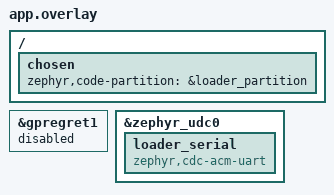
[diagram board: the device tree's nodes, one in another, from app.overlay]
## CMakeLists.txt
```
# SPDX-License-Identifier: MIT
#
# The Neuron's UF2 loader, linked at 0x1000 in front of ZMK. Build it for
# defy_neuron/nrf52833; this module is its board root.

cmake_minimum_required(VERSION 3.20.0)

get_filename_component(module ${CMAKE_CURRENT_LIST_DIR}/../.. ABSOLUTE)
list(APPEND BOARD_ROOT ${module})
list(APPEND DTS_ROOT ${module})

find_package(Zephyr REQUIRED HINTS $ENV{ZEPHYR_BASE})
project(defy_loader)

# src/start.c replaces the soc_reset_hook binding in Nordic's platform_init.ld,
# and Zephyr's Cortex-M reset.S calls the hook before SystemInit(). Another
# version of either file stops the build until start.c is reviewed against it.
include(${module}/cmake/defy_upstream.cmake)
defy_upstream_pin(${ZEPHYR_BASE}/soc/nordic/common/platform_init.ld
                  2e75270bf5d0bfbcefe237fb653c8c4a975bf787b9f60406268f4a7f0cc7279c
                  "the loader's src/start.c")
defy_upstream_pin(${ZEPHYR_BASE}/arch/arm/core/cortex_m/reset.S
                  3245028db3c46e9ed273d4e981f1776d7d1741a02d1fbda7d18617a81e82e74c
                  "the loader's src/start.c")

target_include_directories(app PRIVATE src ${module}/include)
target_sources(app PRIVATE src/start.c src/boot_mode.c src/main.c src/disk.c src/uf2.c
                           src/fat.c src/led.c)
```

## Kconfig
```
# SPDX-License-Identifier: MIT

mainmenu "Defy Neuron UF2 loader"

menu "Defy UF2 loader"

# Placeholder IDs, Zephyr's for testing. They differ from ZMK's 1d50:615e
# because Windows binds drivers by these IDs.
config DEFY_LOADER_USB_VID
    hex "USB vendor ID of the drive"
    default 0x2fe3

config DEFY_LOADER_USB_PID
    hex "USB product ID of the drive"
    default 0x0100

config DEFY_LOADER_USB_MANUFACTURER
    string "USB manufacturer string of the drive"
    default "zmk-defy-wireless"

config DEFY_LOADER_USB_PRODUCT
    string "USB product string of the drive"
    default "Defy UF2 loader"

endmenu

source "Kconfig.zephyr"
```

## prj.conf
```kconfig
# SPDX-License-Identifier: MIT

# The drive: Zephyr's USB device stack with its mass storage and CDC ACM
# classes, one instance each. The serial number comes from hwinfo, as ZMK's
# does; Kconfig in this directory holds the IDs and strings.
CONFIG_USB_DEVICE_STACK_NEXT=y
CONFIG_USBD_MSC_CLASS=y
CONFIG_USBD_CDC_ACM_CLASS=y
CONFIG_HWINFO=y
CONFIG_SERIAL=y
CONFIG_UART_LINE_CTRL=y

# ZMK's code_partition and Dygma's boot request page.
CONFIG_FLASH=y
CONFIG_FLASH_MAP=y
CONFIG_FLASH_PAGE_LAYOUT=y
CONFIG_CRC=y

CONFIG_REBOOT=y
CONFIG_POWEROFF=y

# Nothing reads a log or a console without SWD.
CONFIG_LOG=n
CONFIG_PRINTK=n
CONFIG_CONSOLE=n
CONFIG_BOOT_BANNER=n

# The loader drives no pins but the status LED's, through nrfx's PWM
# registers (src/led.c).
CONFIG_GPIO=n

# Size: the loader has 48 KiB.
CONFIG_LTO=y
CONFIG_ISR_TABLES_LOCAL_DECLARATION=y
CONFIG_COMMON_LIBC_MALLOC=n
CONFIG_TIMESLICING=n
CONFIG_ERRNO=n
CONFIG_FAULT_DUMP=0
```

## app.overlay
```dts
/*
 * The loader runs from loader_partition at 0x1000, where n2_bootloader starts
 * it; code_partition is ZMK's. loader_serial takes the installer's 1200-baud
 * request for n2_bootloader.
 *
 * SPDX-License-Identifier: MIT
 */

/ {
    chosen {
        zephyr,code-partition = &loader_partition;
    };
};

/* No driver for GPREGRET: start.c and main.c own it. */
&gpregret1 {
    status = "disabled";
};

&zephyr_udc0 {
    loader_serial: loader_serial {
        compatible = "zephyr,cdc-acm-uart";
    };
};
```

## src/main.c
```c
/*
 * The loader's drive mode, reached when start.c did not start ZMK. The
 * Neuron shows a USB drive that takes a UF2 file of ZMK (disk.c), and a
 * serial port, and its status LED (led.c) shows what a reset would start.
 * Setting the port to 1200 baud with DTR low, and keeping it so for 250 ms,
 * writes Dygma's boot request and resets into n2_bootloader, as ZMK's Studio
 * port does (docs/software-bootloader.md).
 *
 * ZMK can start when its vector table is valid and start.c did not stop it
 * for failing to confirm its starts. The loader leaves drive mode by a reset
 * into ZMK once a UF2 file has been written; when VBUS goes away while ZMK
 * can start; after a fatal error; and, for a drive shown on request, after
 * IDLE_TIMEOUT_MIN minutes without a UF2 block. Otherwise a VBUS loss powers
 * the Neuron down to System OFF, from which a USB connection wakes it into
 * the drive again. A failed setup, the disk's check included, leaves the
 * same way, except that while VBUS stays and ZMK cannot start, the loader
 * waits for VBUS to go: a reset would only fail again.
 *
 * SPDX-License-Identifier: MIT
 */

#include <errno.h>

#include <zephyr/device.h>
#include <zephyr/drivers/uart.h>
#include <zephyr/fatal.h>
#include <zephyr/kernel.h>
#include <zephyr/storage/flash_map.h>
#include <zephyr/sys/poweroff.h>
#include <zephyr/sys/reboot.h>
#include <zephyr/usb/usbd.h>
#include <hal/nrf_power.h>

#include <dygma/defy_boot_request.h>
#include <dygma/defy_loader.h>

#include "boot_mode.h"
#include "layout.h"
#include "loader.h"

/* The loader runs from loader_partition (app.overlay), and layout.h agrees with the
 * devicetree, which ZMK's board shares. */
BUILD_ASSERT(DT_SAME_NODE(DT_CHOSEN(zephyr_code_partition), DT_NODELABEL(loader_partition)));
BUILD_ASSERT(CONFIG_FLASH_LOAD_OFFSET == FIXED_PARTITION_OFFSET(loader_partition) &&
             CONFIG_FLASH_LOAD_SIZE == FIXED_PARTITION_SIZE(loader_partition));
BUILD_ASSERT(FIXED_PARTITION_OFFSET(loader_partition) + FIXED_PARTITION_SIZE(loader_partition) ==
             DEFY_LOADER_ZMK_START);
BUILD_ASSERT(FIXED_PARTITION_OFFSET(code_partition) == DEFY_LOADER_ZMK_START);
BUILD_ASSERT(FIXED_PARTITION_OFFSET(code_partition) + FIXED_PARTITION_SIZE(code_partition) ==
             DEFY_LOADER_ZMK_END);
BUILD_ASSERT(DT_REG_ADDR(DT_CHOSEN(zephyr_sram)) == DEFY_LOADER_RAM_START &&
             DT_REG_ADDR(DT_CHOSEN(zephyr_sram)) + DT_REG_SIZE(DT_CHOSEN(zephyr_sram)) ==
                 DEFY_LOADER_RAM_END);
BUILD_ASSERT(DT_PROP(DT_CHOSEN(zephyr_flash), erase_block_size) == DEFY_LOADER_PAGE_SIZE);

/* After a complete file, the host has this long to finish its own writes. */
#define COPIED_RESET_DELAY_MS 500
/* A drive shown on request, with a valid ZMK, goes back to ZMK after this long without
 * a UF2 block: after a stray press of the key, on a charger, or once the host has
 * ejected the drive. */
#define IDLE_TIMEOUT_MIN 5
/* bMaxPower, in 2 mA units, as in ZMK's build. */
#define MAX_POWER 50
/* How often a failed setup checks whether VBUS has gone. */
#define VBUS_POLL_MS 100

USBD_DEVICE_DEFINE(loader_usbd, DEVICE_DT_GET(DT_NODELABEL(zephyr_udc0)),
                   CONFIG_DEFY_LOADER_USB_VID, CONFIG_DEFY_LOADER_USB_PID);
USBD_DESC_LANG_DEFINE(loader_language);
USBD_DESC_MANUFACTURER_DEFINE(loader_manufacturer, CONFIG_DEFY_LOADER_USB_MANUFACTURER);
USBD_DESC_PRODUCT_DEFINE(loader_product, CONFIG_DEFY_LOADER_USB_PRODUCT);
/* ZMK's serial number: hwinfo's eight-byte device ID as 16 uppercase hex digits. */
USBD_DESC_SERIAL_NUMBER_DEFINE(loader_serial_number);
USBD_CONFIGURATION_DEFINE(loader_configuration, USB_SCD_SELF_POWERED, MAX_POWER, NULL);

static const struct device *const serial = DEVICE_DT_GET(DT_NODELABEL(loader_serial));

bool defy_loader_zmk_startable(void) {
    const volatile uint32_t *vectors = (const volatile uint32_t *)DEFY_LOADER_ZMK_START;
    return defy_loader_zmk_valid(vectors[0], vectors[1]) &&
           defy_loader_starts(nrf_power_gpregret_get(NRF_POWER, DEFY_LOADER_GPREGRET)) <
               DEFY_LOADER_START_LIMIT;
}

/* With GPREGRET cleared, start.c starts ZMK after the reset if it is valid, with a fresh
 * count of its starts. */
static FUNC_NORETURN void restart(void) {
    nrf_power_gpregret_set(NRF_POWER, DEFY_LOADER_GPREGRET, 0);
    sys_reboot(SYS_REBOOT_COLD);
}

/*
 * Into ZMK if it can start, otherwise to System OFF. Only a USB connection wakes the
 * Neuron from System OFF, and VBUS that is still there, or already back, would never
 * bring one, so then a reset shows the drive again at once.
 */
static FUNC_NORETURN void leave(void) {
    if (defy_loader_zmk_startable()) {
        restart();
    }
    (void)usbd_disable(&loader_usbd);
    if (nrf_power_usbregstatus_vbusdet_get(NRF_POWER)) {
        sys_reboot(SYS_REBOOT_COLD);
    }
    defy_loader_led_off();
    sys_poweroff();
}

/* The drive could not be set up. A reset would start the loader into the same
 * failure, so while ZMK cannot start, the LED shows red until VBUS goes and
 * leave() powers the Neuron down; the next USB connection tries again. */
static FUNC_NORETURN void setup_failed(void) {
    while (!defy_loader_zmk_startable() && nrf_power_usbregstatus_vbusdet_get(NRF_POWER)) {
        k_sleep(K_MSEC(VBUS_POLL_MS));
    }
    leave();
}

/* A fatal error restarts the Neuron, which starts ZMK if it is valid, where Zephyr's
 * default handler would halt it. */
void k_sys_fatal_error_handler(unsigned int reason, const struct arch_esf *esf) {
    ARG_UNUSED(reason);
    ARG_UNUSED(esf);
    restart();
}

static void copied(struct k_work *work) {
    ARG_UNUSED(work);
    restart();
}

static K_WORK_DELAYABLE_DEFINE(copied_work, copied);

void defy_loader_copied(void) { k_work_schedule(&copied_work, K_MSEC(COPIED_RESET_DELAY_MS)); }

static void idle(struct k_work *work) {
    ARG_UNUSED(work);
    if (!defy_loader_disk_written() && defy_loader_zmk_startable()) {
        restart();
    }
}

static K_WORK_DELAYABLE_DEFINE(idle_work, idle);

/* n2_bootloader starts the loader again afterwards, and GPREGRET cleared gives the ZMK
 * it then finds a fresh count of its starts. */
static void touch_check(struct k_work *work) {
    ARG_UNUSED(work);
    uint32_t baud;
    uint32_t dtr;
    if (!uart_line_ctrl_get(serial, UART_LINE_CTRL_BAUD_RATE, &baud) &&
        !uart_line_ctrl_get(serial, UART_LINE_CTRL_DTR, &dtr) && baud == DEFY_BOOT_TOUCH_BAUD &&
        dtr == 0 && !defy_boot_request_write()) {
        restart();
    }
}

static K_WORK_DELAYABLE_DEFINE(touch_work, touch_check);

/* The stack delivers these on the system work queue. */
static void usb_message(struct usbd_context *const context, const struct usbd_msg *const msg) {
    uint32_t baud;
    switch (msg->type) {
    case USBD_MSG_VBUS_READY:
        /* main() may have enabled the stack already. */
        (void)usbd_enable(context);
        break;
    case USBD_MSG_VBUS_REMOVED:
        leave();
    case USBD_MSG_CDC_ACM_LINE_CODING:
        if (msg->dev == serial && !uart_line_ctrl_get(serial, UART_LINE_CTRL_BAUD_RATE, &baud) &&
            baud == DEFY_BOOT_TOUCH_BAUD) {
            k_work_schedule(&touch_work, K_MSEC(DEFY_BOOT_TOUCH_DELAY_MS));
        }
        break;
    default:
        break;
    }
}

static int usb_init(void) {
    int err = usbd_add_descriptor(&loader_usbd, &loader_language);
    if (!err) {
        err = usbd_add_descriptor(&loader_usbd, &loader_manufacturer);
    }
    if (!err) {
        err = usbd_add_descriptor(&loader_usbd, &loader_product);
    }
    if (!err) {
        err = usbd_add_descriptor(&loader_usbd, &loader_serial_number);
    }
    if (!err) {
        err = usbd_add_configuration(&loader_usbd, USBD_SPEED_FS, &loader_configuration);
    }
    if (!err) {
        err = usbd_register_all_classes(&loader_usbd, USBD_SPEED_FS, 1, NULL);
    }
    if (!err) {
        /* CDC ACM has two interfaces under an interface association descriptor. */
        err = usbd_device_set_code_triple(&loader_usbd, USBD_SPEED_FS, USB_BCC_MISCELLANEOUS,
                                          0x02, 0x01);
    }
    if (!err) {
        usbd_self_powered(&loader_usbd, true);
        err = usbd_msg_register_cb(&loader_usbd, usb_message);
    }
    return err ? err : usbd_init(&loader_usbd);
}

int main(void) {
    /* A startable ZMK means the drive was requested: go back to ZMK after IDLE_TIMEOUT_MIN
     * without a UF2 block. */
    if (defy_loader_zmk_startable()) {
        k_work_schedule(&idle_work, K_MINUTES(IDLE_TIMEOUT_MIN));
    }
    if (!nrf_power_usbregstatus_vbusdet_get(NRF_POWER)) {
        leave();
    }
    defy_loader_led_init();
    if (defy_loader_disk_init() || usb_init()) {
        setup_failed();
    }
    /*
     * VBUS is present, so enable the stack now: USBD_MSG_VBUS_READY comes from the
     * USB-detected event, which an earlier stage may already have taken.
     */
    int err = usbd_enable(&loader_usbd);
    if (err && err != -EALREADY) {
        setup_failed();
    }
    return 0;
}
```

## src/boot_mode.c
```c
/* SPDX-License-Identifier: MIT */

#include <dygma/defy_loader.h>

#include "boot_mode.h"
#include "layout.h"

/* GPREGRET holds 8 bits, and the drive request is not a count of starts. */
_Static_assert(DEFY_LOADER_STARTS(DEFY_LOADER_START_LIMIT) <= 0xffu, "The count fits GPREGRET");
_Static_assert(DEFY_LOADER_DRIVE_MAGIC != 0 &&
                   (DEFY_LOADER_DRIVE_MAGIC <= DEFY_LOADER_STARTS_BASE ||
                    DEFY_LOADER_DRIVE_MAGIC > DEFY_LOADER_STARTS(DEFY_LOADER_START_LIMIT)),
               "The drive request differs from every count");

bool defy_loader_zmk_valid(uint32_t stack, uint32_t reset) {
    uint32_t entry = reset & ~1u;
    return stack % 4 == 0 && stack > DEFY_LOADER_RAM_START && stack <= DEFY_LOADER_RAM_END &&
           (reset & 1u) != 0 && entry >= DEFY_LOADER_ZMK_START && entry < DEFY_LOADER_ZMK_END;
}

enum defy_loader_start defy_loader_start_mode(uint32_t gpregret, uint32_t stack, uint32_t reset) {
    if (gpregret == DEFY_LOADER_DRIVE_MAGIC) {
        return DEFY_LOADER_DRIVE_REQUESTED;
    }
    if (!defy_loader_zmk_valid(stack, reset)) {
        return DEFY_LOADER_DRIVE_NO_ZMK;
    }
    return defy_loader_starts(gpregret) < DEFY_LOADER_START_LIMIT ? DEFY_LOADER_START_ZMK
                                                                  : DEFY_LOADER_DRIVE_ZMK_FAILED;
}

uint32_t defy_loader_start_gpregret(enum defy_loader_start mode, uint32_t gpregret) {
    switch (mode) {
    case DEFY_LOADER_START_ZMK:
        return DEFY_LOADER_STARTS(defy_loader_starts(gpregret) + 1);
    case DEFY_LOADER_DRIVE_ZMK_FAILED:
        return DEFY_LOADER_STARTS(DEFY_LOADER_START_LIMIT);
    default:
        return 0;
    }
}
```

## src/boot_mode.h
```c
/*
 * The loader's start decision, made by start.c before anything else runs,
 * from GPREGRET (<dygma/defy_loader.h>) and ZMK's vector table.
 *
 * SPDX-License-Identifier: MIT
 */

#pragma once

#include <stdbool.h>
#include <stdint.h>

enum defy_loader_start {
    /* ZMK's vector table is valid and its unconfirmed starts are below the limit:
     * start ZMK. */
    DEFY_LOADER_START_ZMK,
    /* GPREGRET holds the drive request: show the drive. */
    DEFY_LOADER_DRIVE_REQUESTED,
    /* No valid ZMK: show the drive. */
    DEFY_LOADER_DRIVE_NO_ZMK,
    /* ZMK started DEFY_LOADER_START_LIMIT times in a row without confirming: show
     * the drive. */
    DEFY_LOADER_DRIVE_ZMK_FAILED,
};

/*
 * True if stack and reset, the first two words at ZMK's start, can start ZMK:
 * a word-aligned stack pointer inside RAM, and a Thumb reset vector inside
 * ZMK's range.
 */
bool defy_loader_zmk_valid(uint32_t stack, uint32_t reset);

/* What to do with GPREGRET's value and ZMK's first two words. */
enum defy_loader_start defy_loader_start_mode(uint32_t gpregret, uint32_t stack, uint32_t reset);

/*
 * GPREGRET's value for a start in mode, from its value before: one more
 * unconfirmed start for ZMK, the limit kept while ZMK has failed, and 0 when
 * the drive shows for any other reason. With the limit kept, drive mode tells
 * a failed ZMK from a requested drive, and a reset after it, other than one
 * that clears GPREGRET, shows the drive again.
 */
uint32_t defy_loader_start_gpregret(enum defy_loader_start mode, uint32_t gpregret);
```

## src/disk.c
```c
/*
 * The drive's disk, for Zephyr's mass storage class. Reads come from the
 * emulated FAT volume (fat.c). Writes go to the UF2 writer (uf2.c), which
 * writes ZMK's code_partition through the flash map, so no write reaches
 * outside it. Sectors that hold no UF2 block, such as the FAT, directories
 * and the host's metadata files, are dropped.
 *
 * SPDX-License-Identifier: MIT
 */

#include <errno.h>

#include <zephyr/drivers/disk.h>
#include <zephyr/storage/disk_access.h>
#include <zephyr/storage/flash_map.h>
#include <zephyr/usb/class/usbd_msc.h>

#include "fat.h"
#include "layout.h"
#include "loader.h"
#include "uf2.h"

#define DISK_NAME "UF2"

BUILD_ASSERT(DEFY_FAT_SECTOR_SIZE == DEFY_UF2_BLOCK_SIZE);
BUILD_ASSERT(DEFY_FAT_SECTOR_SIZE <= CONFIG_USBD_MSC_SCSI_BUFFER_SIZE);
BUILD_ASSERT(sizeof(DEFY_LOADER_VERSION) == 4, "The INQUIRY revision takes 4 characters");

/* The drive's one logical unit. The SCSI INQUIRY strings are padded with spaces to their
 * fields' widths: 8, 16 and 4 characters. */
USBD_DEFINE_MSC_LUN(uf2, DISK_NAME, "Defy    ", "UF2 loader      ", DEFY_LOADER_VERSION " ");

static const struct flash_area *code_area;
static struct defy_uf2_file file;

static int flash_erase(void *context, uint32_t address) {
    ARG_UNUSED(context);
    return flash_area_erase(code_area, address - DEFY_LOADER_ZMK_START, DEFY_LOADER_PAGE_SIZE);
}

static int flash_write(void *context, uint32_t address, const void *data, size_t length) {
    ARG_UNUSED(context);
    return flash_area_write(code_area, address - DEFY_LOADER_ZMK_START, data, length);
}

static int flash_read(void *context, uint32_t address, void *data, size_t length) {
    ARG_UNUSED(context);
    return flash_area_read(code_area, address - DEFY_LOADER_ZMK_START, data, length);
}

static const struct defy_uf2_flash flash = {
    .erase = flash_erase,
    .write = flash_write,
    .read = flash_read,
};

static int disk_init(struct disk_info *disk) {
    ARG_UNUSED(disk);
    return 0;
}

static int disk_status(struct disk_info *disk) {
    ARG_UNUSED(disk);
    return DISK_STATUS_OK;
}

static int disk_read(struct disk_info *disk, uint8_t *data, uint32_t start, uint32_t count) {
    ARG_UNUSED(disk);
    for (uint32_t i = 0; i < count; i++) {
        defy_fat_read(start + i, data + i * DEFY_FAT_SECTOR_SIZE);
    }
    return 0;
}

static int disk_write(struct disk_info *disk, const uint8_t *data, uint32_t start,
                      uint32_t count) {
    ARG_UNUSED(disk);
    ARG_UNUSED(start);
    int err = 0;
    for (uint32_t i = 0; i < count; i++) {
        struct defy_uf2_block block;
        if (defy_uf2_parse(data + i * DEFY_UF2_BLOCK_SIZE, &block) != DEFY_UF2_BLOCK) {
            continue;
        }
        switch (defy_uf2_file_add(&file, &block, &flash)) {
        case DEFY_UF2_STORED:
            defy_loader_led_block();
            break;
        case DEFY_UF2_COMPLETE:
            defy_loader_led_block();
            defy_loader_copied();
            break;
        case DEFY_UF2_FAILED:
            err = -EIO;
            break;
        default:
            break;
        }
    }
    return err;
}

static int disk_ioctl(struct disk_info *disk, uint8_t command, void *value) {
    ARG_UNUSED(disk);
    switch (command) {
    case DISK_IOCTL_GET_SECTOR_COUNT:
        *(uint32_t *)value = DEFY_FAT_SECTOR_COUNT;
        return 0;
    case DISK_IOCTL_GET_SECTOR_SIZE:
        *(uint32_t *)value = DEFY_FAT_SECTOR_SIZE;
        return 0;
    case DISK_IOCTL_GET_ERASE_BLOCK_SZ:
        *(uint32_t *)value = 1;
        return 0;
    case DISK_IOCTL_CTRL_SYNC:
    case DISK_IOCTL_CTRL_INIT:
    case DISK_IOCTL_CTRL_DEINIT:
        return 0;
    default:
        return -EINVAL;
    }
}

static const struct disk_operations disk_operations = {
    .init = disk_init,
    .status = disk_status,
    .read = disk_read,
    .write = disk_write,
    .ioctl = disk_ioctl,
};

static struct disk_info disk = {
    .name = DISK_NAME,
    .ops = &disk_operations,
};

/* The disk as the mass storage class finds it, by name through Zephyr's disk access:
 * ready, with the volume's sector count and size, and a boot sector that ends in the
 * FAT signature. */
static int disk_check(void) {
    static uint8_t sector[DEFY_FAT_SECTOR_SIZE];
    uint32_t count = 0;
    uint32_t size = 0;
    if (disk_access_status(DISK_NAME) != DISK_STATUS_OK ||
        disk_access_ioctl(DISK_NAME, DISK_IOCTL_GET_SECTOR_COUNT, &count) ||
        disk_access_ioctl(DISK_NAME, DISK_IOCTL_GET_SECTOR_SIZE, &size) ||
        count != DEFY_FAT_SECTOR_COUNT || size != DEFY_FAT_SECTOR_SIZE ||
        disk_access_read(DISK_NAME, sector, 0, 1) ||
        sector[DEFY_FAT_SECTOR_SIZE - 2] != 0x55 || sector[DEFY_FAT_SECTOR_SIZE - 1] != 0xaa) {
        return -EIO;
    }
    return 0;
}

int defy_loader_disk_init(void) {
    int err = flash_area_open(FIXED_PARTITION_ID(code_partition), &code_area);
    if (!err) {
        defy_uf2_file_init(&file);
        err = disk_access_register(&disk);
    }
    return err ? err : disk_check();
}

bool defy_loader_disk_written(void) { return file.state != DEFY_UF2_IDLE; }
```

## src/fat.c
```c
/* SPDX-License-Identifier: MIT */

#include <stddef.h>
#include <string.h>

#include "fat.h"

#define RESERVED_SECTORS 1u
#define FAT_COUNT 2u
#define SECTORS_PER_FAT 32u
/* The usual FAT16 root directory, 32 sectors: room for the metadata files hosts add. */
#define ROOT_ENTRIES 512u
#define DIRECTORY_ENTRY_SIZE 32u
#define ROOT_SECTORS (ROOT_ENTRIES * DIRECTORY_ENTRY_SIZE / DEFY_FAT_SECTOR_SIZE)
#define FAT_START RESERVED_SECTORS
#define ROOT_START (FAT_START + FAT_COUNT * SECTORS_PER_FAT)
#define DATA_START (ROOT_START + ROOT_SECTORS)
/* One sector per cluster; data clusters are numbered from 2. */
#define CLUSTERS (DEFY_FAT_SECTOR_COUNT - DATA_START)
#define FIRST_CLUSTER 2u

#define FAT16_END_OF_CHAIN 0xffffu
#define FAT16_MEDIA 0xfff8u

#define ATTRIBUTE_READ_ONLY 0x01u
#define ATTRIBUTE_VOLUME_ID 0x08u
/* 2026-10-27 12:00, in FAT's date and time formats. */
#define FILE_DATE (((2026u - 1980u) << 9) | (10u << 5) | 27u)
#define FILE_TIME (12u << 11)

_Static_assert(CLUSTERS >= 4085 && CLUSTERS < 65525, "The cluster count makes a FAT16 volume");
_Static_assert((CLUSTERS + FIRST_CLUSTER) * 2 <= SECTORS_PER_FAT * DEFY_FAT_SECTOR_SIZE,
               "Each FAT holds an entry for every cluster");

#define VOLUME_LABEL "DEFY       "

static const char info[] = "UF2 Bootloader " DEFY_LOADER_VERSION " zmk-defy-wireless\r\n"
                           "Model: Dygma Neuron (wireless)\r\n"
                           "Board-ID: " DEFY_LOADER_BOARD_ID "\r\n";

static const char index_page[] =
    "<!doctype html>\n"
    "<html><head><meta http-equiv=\"refresh\" "
    "content=\"0;URL='https://github.com/borovaka/zmk-defy-wireless#readme'\"></head>\n"
    "<body><a href=\"https://github.com/borovaka/zmk-defy-wireless#readme\">"
    "zmk-defy-wireless</a></body></html>\n";

struct file {
    /* 8.3 name, padded with spaces, without the dot. */
    char name[11];
    const char *content;
    uint32_t size;
};

/* Each file takes one cluster, from FIRST_CLUSTER on in this order. */
static const struct file files[] = {
    {{'I', 'N', 'F', 'O', '_', 'U', 'F', '2', 'T', 'X', 'T'}, info, sizeof(info) - 1},
    {{'I', 'N', 'D', 'E', 'X', ' ', ' ', ' ', 'H', 'T', 'M'}, index_page, sizeof(index_page) - 1},
};

#define FILE_COUNT (sizeof(files) / sizeof(files[0]))

_Static_assert(sizeof(info) - 1 <= DEFY_FAT_SECTOR_SIZE, "INFO_UF2.TXT fits one cluster");
_Static_assert(sizeof(index_page) - 1 <= DEFY_FAT_SECTOR_SIZE, "INDEX.HTM fits one cluster");

static void put_le16(uint8_t *bytes, uint16_t value) {
    bytes[0] = value & 0xff;
    bytes[1] = value >> 8;
}

static void put_le32(uint8_t *bytes, uint32_t value) {
    put_le16(bytes, value & 0xffff);
    put_le16(bytes + 2, value >> 16);
}

static void boot_sector(uint8_t *sector) {
    static const uint8_t jump[] = {0xeb, 0x3c, 0x90};
    memcpy(sector, jump, sizeof(jump));
    memcpy(sector + 3, "MSWIN4.1", 8);
    put_le16(sector + 11, DEFY_FAT_SECTOR_SIZE);
    sector[13] = 1; /* sectors per cluster */
    put_le16(sector + 14, RESERVED_SECTORS);
    sector[16] = FAT_COUNT;
    put_le16(sector + 17, ROOT_ENTRIES);
    put_le16(sector + 19, DEFY_FAT_SECTOR_COUNT);
    sector[21] = FAT16_MEDIA & 0xff;
    put_le16(sector + 22, SECTORS_PER_FAT);
    put_le16(sector + 24, 1); /* sectors per track */
    put_le16(sector + 26, 1); /* heads */
    sector[36] = 0x80;        /* drive number */
    sector[38] = 0x29;        /* extended boot signature: the next three fields */
    put_le32(sector + 39, 0x44454659u);
    memcpy(sector + 43, VOLUME_LABEL, 11);
    memcpy(sector + 54, "FAT16   ", 8);
    sector[510] = 0x55;
    sector[511] = 0xaa;
}

static void fat_sector(uint32_t index, uint8_t *sector) {
    if (index != 0) {
        return;
    }
    put_le16(sector, FAT16_MEDIA);
    put_le16(sector + 2, FAT16_END_OF_CHAIN);
    for (uint32_t i = 0; i < FILE_COUNT; i++) {
        put_le16(sector + (FIRST_CLUSTER + i) * 2, FAT16_END_OF_CHAIN);
    }
}

static void directory_entry(uint8_t *entry, const char *name, uint8_t attributes,
                            uint16_t cluster, uint32_t size) {
    memcpy(entry, name, 11);
    entry[11] = attributes;
    put_le16(entry + 14, FILE_TIME); /* created */
    put_le16(entry + 16, FILE_DATE);
    put_le16(entry + 18, FILE_DATE); /* accessed */
    put_le16(entry + 22, FILE_TIME); /* written */
    put_le16(entry + 24, FILE_DATE);
    put_le16(entry + 26, cluster);
    put_le32(entry + 28, size);
}

static void root_sector(uint32_t index, uint8_t *sector) {
    if (index != 0) {
        return;
    }
    directory_entry(sector, VOLUME_LABEL, ATTRIBUTE_VOLUME_ID, 0, 0);
    for (uint32_t i = 0; i < FILE_COUNT; i++) {
        directory_entry(sector + (i + 1) * DIRECTORY_ENTRY_SIZE, files[i].name,
                        ATTRIBUTE_READ_ONLY, FIRST_CLUSTER + i, files[i].size);
    }
}

void defy_fat_read(uint32_t sector, uint8_t *buffer) {
    memset(buffer, 0, DEFY_FAT_SECTOR_SIZE);
    if (sector == 0) {
        boot_sector(buffer);
    } else if (sector < ROOT_START) {
        fat_sector((sector - FAT_START) % SECTORS_PER_FAT, buffer);
    } else if (sector < DATA_START) {
        root_sector(sector - ROOT_START, buffer);
    } else if (sector - DATA_START < FILE_COUNT) {
        const struct file *file = &files[sector - DATA_START];
        memcpy(buffer, file->content, file->size);
    }
}
```

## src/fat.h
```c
/*
 * The drive's FAT16 volume, labelled DEFY, generated on each read: a boot
 * sector, two FATs, a root directory with INFO_UF2.TXT and INDEX.HTM, and
 * free clusters for the host's copy of a UF2 file. Nothing a host writes
 * changes it; uf2.c takes the UF2 blocks out of those writes.
 *
 * SPDX-License-Identifier: MIT
 */

#pragma once

#include <stdint.h>

/* The loader's version, in INFO_UF2.TXT and in the drive's SCSI INQUIRY data. */
#define DEFY_LOADER_VERSION "1.1"
/* INFO_UF2.TXT's Board-ID, which the zmk variant's uf2 runner matches
 * (boards/dygma/defy_neuron/board.cmake): chip, board and revision, in the form
 * Adafruit's and Microsoft's UF2 bootloaders use. */
#define DEFY_LOADER_BOARD_ID "nRF52833-DefyNeuron-v1"

#define DEFY_FAT_SECTOR_SIZE 512u
/* 4 MiB. Its 8095 one-sector clusters make it FAT16, and all but two are free: a UF2 file
 * of ZMK's whole range takes 1520. */
#define DEFY_FAT_SECTOR_COUNT 8192u

/* Fills buffer, DEFY_FAT_SECTOR_SIZE bytes, with the sector; zeros past the end. */
void defy_fat_read(uint32_t sector, uint8_t *buffer);
```

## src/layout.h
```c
/*
 * The Neuron's flash and RAM as the loader uses them. The flash ranges come
 * from boards/dygma/defy_neuron/defy_neuron-partitions.dtsi, and main.c
 * checks at build time that the two agree. The files that hold no Zephyr code
 * (boot_mode.c, uf2.c, fat.c) take them from here, so that the host
 * suites in tests/host/ can build them. tests/scripts/test_loader_layout.py
 * compares the partitions with scripts/neuron_image.py.
 *
 * SPDX-License-Identifier: MIT
 */

#pragma once

/* ZMK's code_partition, the only range the loader writes. */
#define DEFY_LOADER_ZMK_START 0xd000u
#define DEFY_LOADER_ZMK_END 0x6c000u

/* The nRF52833's flash page, the unit of an erase. */
#define DEFY_LOADER_PAGE_SIZE 0x1000u

/* The nRF52833's RAM. */
#define DEFY_LOADER_RAM_START 0x20000000u
#define DEFY_LOADER_RAM_END 0x20020000u
```

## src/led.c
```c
/*
 * The Neuron's status LED in drive mode: amber while ZMK can start, as on a
 * drive shown on request, red while it cannot, and green blinking fast while
 * UF2 blocks for ZMK are written. The brightness is ZMK's default; the loader
 * is built without the keymap's settings.
 *
 * Zephyr's PWM driver would take 3 KB of the loader's 48 KiB, so this file
 * sets up the PWM peripheral through nrfx's register functions. The pins,
 * channels and period come from the led_green and led_red nodes in the plain
 * board's devicetree, which ZMK drives through Zephyr's driver.
 *
 * SPDX-License-Identifier: MIT
 */

#include <zephyr/devicetree.h>
#include <zephyr/dt-bindings/pinctrl/nrf-pinctrl.h>
#include <zephyr/dt-bindings/pwm/pwm.h>
#include <zephyr/kernel.h>
#include <zephyr/sys/atomic.h>
#include <hal/nrf_gpio.h>
#include <hal/nrf_pwm.h>

#include "loader.h"

/* CONFIG_DEFY_NEURON_STATUS_LED_BRIGHTNESS's default in ZMK, in percent. */
#define BRIGHTNESS 3
/* Green's half period while blocks are written. */
#define BLINK_MS 100
/* The blink stops this long after the last block, give or take a blink. */
#define COPY_IDLE_MS 1000

#define GREEN DT_NODELABEL(led_green)
#define RED DT_NODELABEL(led_red)
#define PWM_NODE DT_PWMS_CTLR(GREEN)
/* The pins of the PWM's default state, in channel order. */
#define PINS DT_CHILD(DT_PINCTRL_BY_IDX(PWM_NODE, 0, 0), group1)
#define PSEL(channel) DT_PROP_BY_IDX(PINS, psels, channel)
#define PSEL_PIN(channel) ((PSEL(channel) >> NRF_PIN_POS) & NRF_PIN_MSK)
#define PSEL_FUN(channel) ((PSEL(channel) >> NRF_FUN_POS) & NRF_FUN_MSK)
/* The period in counts of the 16 MHz clock, which COUNTERTOP holds in 15 bits. */
#define TOP (DT_PWMS_PERIOD(GREEN) * 16ull / 1000)
/* An active-high pulse of value counts, as in Zephyr's driver. */
#define DUTY(value) ((uint16_t)((value) | BIT(15)))

BUILD_ASSERT(DT_SAME_NODE(DT_PWMS_CTLR(RED), PWM_NODE));
BUILD_ASSERT(DT_PWMS_CHANNEL(GREEN) == 0 && DT_PWMS_CHANNEL(RED) == 1);
BUILD_ASSERT(DT_PWMS_PERIOD(RED) == DT_PWMS_PERIOD(GREEN));
BUILD_ASSERT(DT_PWMS_FLAGS(GREEN) == PWM_POLARITY_NORMAL &&
             DT_PWMS_FLAGS(RED) == PWM_POLARITY_NORMAL);
BUILD_ASSERT(DT_PROP_LEN(PINS, psels) == 2 && PSEL_FUN(0) == NRF_FUN_PWM_OUT0 &&
             PSEL_FUN(1) == NRF_FUN_PWM_OUT1);
BUILD_ASSERT(TOP > 0 && TOP <= 0x7fff);

static NRF_PWM_Type *const pwm = (NRF_PWM_Type *)DT_REG_ADDR(PWM_NODE);
/* The PWM reads the sequence from RAM at each start. */
static nrf_pwm_values_individual_t duty;
static const nrf_pwm_sequence_t sequence = {
    .values.p_individual = &duty,
    .length = NRF_PWM_VALUES_LENGTH(duty),
};

enum {
    LED_READY,
    LED_COPYING,
    LED_OFF,
};

static atomic_t led_flags;
/* k_uptime_get_32() at the last block. */
static atomic_t last_block;

/* One playback of the sequence: the PWM then holds its values. */
static void show(bool red, bool green) {
    duty.channel_0 = DUTY(green ? TOP * BRIGHTNESS / 100 : 0);
    duty.channel_1 = DUTY(red ? TOP * BRIGHTNESS / 100 : 0);
    nrf_pwm_task_trigger(pwm, NRF_PWM_TASK_SEQSTART0);
}

static void update_led(struct k_work *work);
static K_WORK_DELAYABLE_DEFINE(led_work, update_led);

static void update_led(struct k_work *work) {
    ARG_UNUSED(work);
    if (!atomic_test_bit(&led_flags, LED_READY) || atomic_test_bit(&led_flags, LED_OFF)) {
        return;
    }
    uint32_t now = k_uptime_get_32();
    if (atomic_test_bit(&led_flags, LED_COPYING) &&
        now - (uint32_t)atomic_get(&last_block) < COPY_IDLE_MS) {
        show(false, (now / BLINK_MS) % 2 == 0);
        k_work_schedule(&led_work, K_MSEC(BLINK_MS - now % BLINK_MS));
        return;
    }
    /* A block that arrives now finds the flag clear and runs this again. */
    atomic_clear_bit(&led_flags, LED_COPYING);
    show(true, defy_loader_zmk_startable());
}

void defy_loader_led_init(void) {
    uint32_t pins[NRF_PWM_CHANNEL_COUNT] = {PSEL_PIN(0), PSEL_PIN(1), NRF_PWM_PIN_NOT_CONNECTED,
                                            NRF_PWM_PIN_NOT_CONNECTED};
    /* Low while the PWM is off, as Zephyr's pin control leaves them. */
    for (int i = 0; i < 2; i++) {
        nrf_gpio_pin_clear(pins[i]);
        nrf_gpio_cfg_output(pins[i]);
    }
    nrf_pwm_pins_set(pwm, pins);
    nrf_pwm_configure(pwm, NRF_PWM_CLK_16MHz, NRF_PWM_MODE_UP, TOP);
    nrf_pwm_decoder_set(pwm, NRF_PWM_LOAD_INDIVIDUAL, NRF_PWM_STEP_AUTO);
    nrf_pwm_sequence_set(pwm, 0, &sequence);
    nrf_pwm_enable(pwm);
    atomic_set_bit(&led_flags, LED_READY);
    k_work_schedule(&led_work, K_NO_WAIT);
}

void defy_loader_led_block(void) {
    atomic_set(&last_block, (atomic_val_t)k_uptime_get_32());
    if (!atomic_test_and_set_bit(&led_flags, LED_COPYING)) {
        k_work_schedule(&led_work, K_NO_WAIT);
    }
}

void defy_loader_led_off(void) {
    atomic_set_bit(&led_flags, LED_OFF);
    /* The pins go back to their GPIO setting, low. */
    nrf_pwm_disable(pwm);
}
```

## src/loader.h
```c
/*
 * Between the parts of drive mode: main.c, the drive's disk (disk.c) and the
 * status LED (led.c).
 *
 * SPDX-License-Identifier: MIT
 */

#pragma once

#include <stdbool.h>

/* Opens ZMK's code_partition, registers the drive's disk and checks it through Zephyr's
 * disk access, as the mass storage class will find it; 0 on success. The flash driver
 * must be ready, so main.c calls it after the kernel's initialisation. The mass storage
 * class looks the disk up by name on each command, and without it answers that no
 * medium is present. */
int defy_loader_disk_init(void);

/* True once a UF2 block for ZMK's range has reached the writer. */
bool defy_loader_disk_written(void);

/* A UF2 file has been written in full: main.c resets into ZMK shortly. */
void defy_loader_copied(void);

/* True if a reset would start ZMK: its vector table is valid, and its unconfirmed
 * starts are below the limit. */
bool defy_loader_zmk_startable(void);

/* Sets up the status LED's PWM and lights the LED for drive mode. */
void defy_loader_led_init(void);

/* A UF2 block has been written, or kept for ZMK's first page: the LED blinks green
 * until COPY_IDLE_MS after the last one. */
void defy_loader_led_block(void);

/* Turns the LED off for good, before System OFF. */
void defy_loader_led_off(void);
```

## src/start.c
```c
/*
 * soc_reset_hook(), the loader's first code after n2_bootloader starts it,
 * ahead of SystemInit() and the rest of Zephyr's start.
 *
 * It decides between ZMK and the drive before anything else runs
 * (boot_mode.c), and writes GPREGRET's new value: one more unconfirmed start
 * before a jump to ZMK, so that a ZMK that keeps failing gets the drive
 * after DEFY_LOADER_START_LIMIT starts. To start ZMK it points VTOR and the
 * main stack at ZMK's vector table and branches to ZMK's reset vector, with
 * the core, clocks and peripherals as n2_bootloader left them, so ZMK starts
 * as it would from n2_bootloader directly and runs its own SystemInit(). For
 * the drive, it runs SystemInit() and returns to Zephyr's start, which ends
 * in main.c.
 *
 * Nordic's SoC support sets soc_reset_hook to SystemInit with PROVIDE() in
 * its linker script, which applies only while nothing else defines the
 * symbol. This definition replaces it. CMakeLists.txt pins that linker
 * script and the Cortex-M reset.S that calls the hook.
 *
 * Zephyr has not set up RAM yet, so this file uses no static variables. It
 * never touches GPREGRET2 or UICR.
 *
 * SPDX-License-Identifier: MIT
 */

#include <stdint.h>

#include <nrf.h>
#include <zephyr/platform/hooks.h>
#include <zephyr/sys/util_macro.h>
#include <zephyr/toolchain.h>

#include "boot_mode.h"
#include "layout.h"

/* reset.S calls soc_reset_hook() only with this option. */
BUILD_ASSERT(IS_ENABLED(CONFIG_SOC_RESET_HOOK));
/* With the CMake linker generator, Nordic binds soc_reset_hook to SystemInit outside
 * platform_init.ld, and that binding would win over this file's. */
BUILD_ASSERT(!IS_ENABLED(CONFIG_CMAKE_LINKER_GENERATOR));

static FUNC_NORETURN void start_zmk(uint32_t stack, uint32_t reset) {
    SCB->VTOR = DEFY_LOADER_ZMK_START;
    __DSB();
    __ISB();
    __asm__ volatile("msr msp, %0\n\t"
                     "bx %1\n\t"
                     :
                     : "r"(stack), "r"(reset)
                     : "memory");
    CODE_UNREACHABLE;
}

void soc_reset_hook(void) {
    const volatile uint32_t *vectors = (const volatile uint32_t *)DEFY_LOADER_ZMK_START;
    uint32_t stack = vectors[0];
    uint32_t reset = vectors[1];
    uint32_t gpregret = NRF_POWER->GPREGRET;
    enum defy_loader_start mode = defy_loader_start_mode(gpregret, stack, reset);

    NRF_POWER->GPREGRET = defy_loader_start_gpregret(mode, gpregret);
    if (mode == DEFY_LOADER_START_ZMK) {
        start_zmk(stack, reset);
    }
    SystemInit();
}
```

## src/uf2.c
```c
/* SPDX-License-Identifier: MIT */

#include <errno.h>
#include <string.h>

#include "uf2.h"

#define MAGIC_START0 0x0a324655u
#define MAGIC_START1 0x9e5d5157u
#define MAGIC_END 0x0ab16f30u

#define FLAG_NOT_MAIN_FLASH 0x00000001u
#define FLAG_FILE_CONTAINER 0x00001000u
#define FLAG_FAMILY_ID 0x00002000u

/* Field offsets in a block. */
#define OFFSET_FLAGS 8
#define OFFSET_ADDRESS 12
#define OFFSET_PAYLOAD_SIZE 16
#define OFFSET_BLOCK_NO 20
#define OFFSET_NUM_BLOCKS 24
#define OFFSET_FAMILY 28
#define OFFSET_DATA 32
#define OFFSET_MAGIC_END (DEFY_UF2_BLOCK_SIZE - 4)

/* ZMK's vector table: its initial stack pointer and reset vector. */
#define VECTORS_SIZE 8u
/* Read-back happens in pieces of this size. */
#define VERIFY_CHUNK 32u

_Static_assert(DEFY_LOADER_ZMK_START % DEFY_LOADER_PAGE_SIZE == 0, "ZMK starts on a page");
_Static_assert(DEFY_LOADER_ZMK_END % DEFY_LOADER_PAGE_SIZE == 0, "ZMK ends on a page");
_Static_assert(DEFY_LOADER_PAGE_SIZE % DEFY_UF2_PAYLOAD_SIZE == 0, "Blocks tile a page");

static uint32_t get_le32(const uint8_t *bytes) {
    return (uint32_t)bytes[0] | (uint32_t)bytes[1] << 8 | (uint32_t)bytes[2] << 16 |
           (uint32_t)bytes[3] << 24;
}

/* Block block_no of num_blocks belongs at address, inside ZMK's range. */
static bool block_fits(uint32_t address, uint32_t block_no, uint32_t num_blocks) {
    return num_blocks != 0 && num_blocks <= DEFY_UF2_MAX_BLOCKS && block_no < num_blocks &&
           address == DEFY_LOADER_ZMK_START + block_no * DEFY_UF2_PAYLOAD_SIZE;
}

enum defy_uf2_check defy_uf2_parse(const uint8_t *sector, struct defy_uf2_block *block) {
    if (get_le32(sector) != MAGIC_START0 || get_le32(sector + 4) != MAGIC_START1) {
        return DEFY_UF2_NOT_UF2;
    }
    uint32_t flags = get_le32(sector + OFFSET_FLAGS);
    uint32_t address = get_le32(sector + OFFSET_ADDRESS);
    uint32_t block_no = get_le32(sector + OFFSET_BLOCK_NO);
    uint32_t num_blocks = get_le32(sector + OFFSET_NUM_BLOCKS);
    if (get_le32(sector + OFFSET_MAGIC_END) != MAGIC_END || !(flags & FLAG_FAMILY_ID) ||
        (flags & (FLAG_NOT_MAIN_FLASH | FLAG_FILE_CONTAINER)) ||
        get_le32(sector + OFFSET_FAMILY) != DEFY_UF2_FAMILY ||
        get_le32(sector + OFFSET_PAYLOAD_SIZE) != DEFY_UF2_PAYLOAD_SIZE ||
        !block_fits(address, block_no, num_blocks)) {
        return DEFY_UF2_REFUSED;
    }
    *block = (struct defy_uf2_block){
        .address = address,
        .block_no = block_no,
        .num_blocks = num_blocks,
        .data = sector + OFFSET_DATA,
    };
    return DEFY_UF2_BLOCK;
}

static bool bit_get(const uint8_t *bits, uint32_t index) {
    return bits[index / 8] & (1u << (index % 8));
}

static void bit_set(uint8_t *bits, uint32_t index) { bits[index / 8] |= 1u << (index % 8); }

static int verify(const struct defy_uf2_flash *flash, uint32_t address, const uint8_t *data,
                  size_t length) {
    uint8_t chunk[VERIFY_CHUNK];
    for (size_t offset = 0; offset < length; offset += sizeof(chunk)) {
        size_t size = length - offset < sizeof(chunk) ? length - offset : sizeof(chunk);
        int err = flash->read(flash->context, address + offset, chunk, size);
        if (err) {
            return err;
        }
        if (memcmp(chunk, data + offset, size) != 0) {
            return -EIO;
        }
    }
    return 0;
}

/*
 * Erases ZMK's first page. Its vector table is first written with zeros, unless it
 * reads as erased or as zeros already. Power lost during the erase can leave the
 * page's words partly erased: an old vector table would still pass start.c's check,
 * while zeros fail it and would need bits to come up into a valid stack pointer and
 * reset vector together. Erased words stay erased. The nRF52833 allows two writes to
 * a word between erases: the vector table's own and this one.
 */
static int erase_first_page(const struct defy_uf2_flash *flash) {
    static const uint8_t zeros[VECTORS_SIZE];
    uint8_t vectors[VECTORS_SIZE];
    int err = flash->read(flash->context, DEFY_LOADER_ZMK_START, vectors, sizeof(vectors));
    if (err) {
        return err;
    }
    bool erased = true;
    for (size_t i = 0; i < sizeof(vectors); i++) {
        erased = erased && vectors[i] == 0xff;
    }
    if (!erased && memcmp(vectors, zeros, sizeof(zeros)) != 0) {
        err = flash->write(flash->context, DEFY_LOADER_ZMK_START, zeros, sizeof(zeros));
    }
    return err ? err : flash->erase(flash->context, DEFY_LOADER_ZMK_START);
}

static enum defy_uf2_result abandon(struct defy_uf2_file *file) {
    file->state = DEFY_UF2_ABANDONED;
    return DEFY_UF2_FAILED;
}

/* Starts the file over, erasing ZMK's first page. False if that failed, which
 * abandons the file. */
static bool start(struct defy_uf2_file *file, uint32_t num_blocks,
                  const struct defy_uf2_flash *flash) {
    defy_uf2_file_init(file);
    file->num_blocks = num_blocks;
    if (erase_first_page(flash)) {
        file->state = DEFY_UF2_ABANDONED;
        return false;
    }
    file->state = DEFY_UF2_RECEIVING;
    bit_set(file->erased, 0);
    return true;
}

/*
 * Writes ZMK's first page from RAM: its body, read back, then its vector table, read
 * back. The vector table is written only over a verified body, and a failure erases
 * the page again.
 */
static int write_first_page(struct defy_uf2_file *file, const struct defy_uf2_flash *flash) {
    const uint32_t body = DEFY_LOADER_ZMK_START + VECTORS_SIZE;
    int err = flash->write(flash->context, body, file->first_page + VECTORS_SIZE,
                           DEFY_LOADER_PAGE_SIZE - VECTORS_SIZE);
    if (!err) {
        err = verify(flash, body, file->first_page + VECTORS_SIZE,
                     DEFY_LOADER_PAGE_SIZE - VECTORS_SIZE);
    }
    if (!err) {
        err = flash->write(flash->context, DEFY_LOADER_ZMK_START, file->first_page,
                           VECTORS_SIZE);
    }
    if (!err) {
        err = verify(flash, DEFY_LOADER_ZMK_START, file->first_page, VECTORS_SIZE);
    }
    if (err) {
        (void)erase_first_page(flash);
    }
    return err;
}

/* True if the block's data equals what the file stored for it. */
static bool stored_same(const struct defy_uf2_file *file, const struct defy_uf2_block *block,
                        const struct defy_uf2_flash *flash) {
    uint32_t offset = block->address - DEFY_LOADER_ZMK_START;
    if (offset < DEFY_LOADER_PAGE_SIZE) {
        return memcmp(file->first_page + offset, block->data, DEFY_UF2_PAYLOAD_SIZE) == 0;
    }
    return verify(flash, block->address, block->data, DEFY_UF2_PAYLOAD_SIZE) == 0;
}

void defy_uf2_file_init(struct defy_uf2_file *file) {
    memset(file, 0, sizeof(*file));
    file->state = DEFY_UF2_IDLE;
    memset(file->first_page, 0xff, sizeof(file->first_page));
}

enum defy_uf2_result defy_uf2_file_add(struct defy_uf2_file *file,
                                       const struct defy_uf2_block *block,
                                       const struct defy_uf2_flash *flash) {
    if (file->state == DEFY_UF2_DONE ||
        !block_fits(block->address, block->block_no, block->num_blocks)) {
        return DEFY_UF2_IGNORED;
    }
    bool restart = block->num_blocks != file->num_blocks;
    if (!restart && file->state == DEFY_UF2_ABANDONED) {
        if (block->block_no != 0) {
            return DEFY_UF2_IGNORED;
        }
        restart = true;
    }
    if (!restart && bit_get(file->blocks, block->block_no)) {
        if (stored_same(file, block, flash)) {
            return DEFY_UF2_IGNORED;
        }
        restart = true;
    }
    if (restart && !start(file, block->num_blocks, flash)) {
        return DEFY_UF2_FAILED;
    }

    uint32_t offset = block->address - DEFY_LOADER_ZMK_START;
    if (offset < DEFY_LOADER_PAGE_SIZE) {
        memcpy(file->first_page + offset, block->data, DEFY_UF2_PAYLOAD_SIZE);
    } else {
        uint32_t page = offset / DEFY_LOADER_PAGE_SIZE;
        if (!bit_get(file->erased, page)) {
            if (flash->erase(flash->context,
                             DEFY_LOADER_ZMK_START + page * DEFY_LOADER_PAGE_SIZE)) {
                return abandon(file);
            }
            bit_set(file->erased, page);
        }
        if (flash->write(flash->context, block->address, block->data, DEFY_UF2_PAYLOAD_SIZE) ||
            verify(flash, block->address, block->data, DEFY_UF2_PAYLOAD_SIZE)) {
            return abandon(file);
        }
    }
    bit_set(file->blocks, block->block_no);
    if (++file->received < file->num_blocks) {
        return DEFY_UF2_STORED;
    }
    if (write_first_page(file, flash)) {
        return abandon(file);
    }
    file->state = DEFY_UF2_DONE;
    return DEFY_UF2_COMPLETE;
}
```
